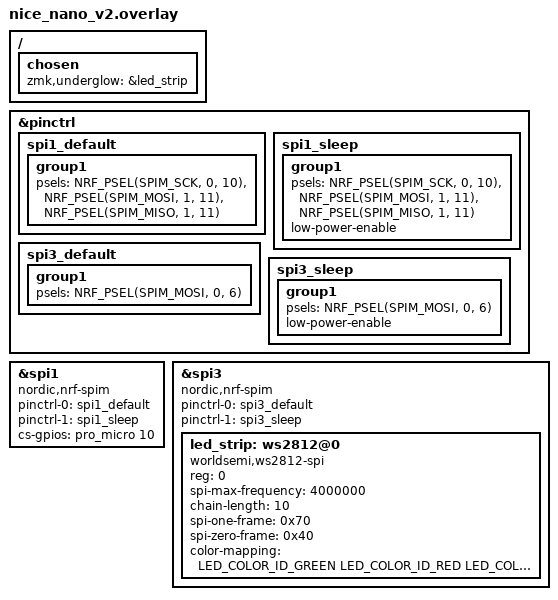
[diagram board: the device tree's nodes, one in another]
#include <dt-bindings/led/led.h>

&pinctrl {
    spi1_default: spi1_default {
        group1 {
            psels = <NRF_PSEL(SPIM_SCK,  0, 10)>,  /* D16 - CL/SCK  */
                    <NRF_PSEL(SPIM_MOSI, 1, 11)>,  /* D14 - DA/MOSI */
                    <NRF_PSEL(SPIM_MISO, 1, 11)>;  /* D14 - MISO (unused, same as MOSI) */
        };
    };
    spi1_sleep: spi1_sleep {
        group1 {
            psels = <NRF_PSEL(SPIM_SCK,  0, 10)>,
                    <NRF_PSEL(SPIM_MOSI, 1, 11)>,
                    <NRF_PSEL(SPIM_MISO, 1, 11)>;
            low-power-enable;
        };
    };
#ifndef MOUSE_PS2_ALT_PINS
    spi3_default: spi3_default {
        group1 {
            psels = <NRF_PSEL(SPIM_MOSI, 0, 6)>;
        };
    };
    spi3_sleep: spi3_sleep {
        group1 {
            psels = <NRF_PSEL(SPIM_MOSI, 0, 6)>;
            low-power-enable;
        };
    };
#endif
};

nice_view_spi: &spi1 {
    compatible = "nordic,nrf-spim";
    status = "okay";
    pinctrl-0 = <&spi1_default>;
    pinctrl-1 = <&spi1_sleep>;
    pinctrl-names = "default", "sleep";
    cs-gpios = <&pro_micro 10 GPIO_ACTIVE_HIGH>;  /* D10 - CS */
};

#ifndef MOUSE_PS2_ALT_PINS
&spi3 {
    compatible = "nordic,nrf-spim";
    status = "okay";
    pinctrl-0 = <&spi3_default>;
    pinctrl-1 = <&spi3_sleep>;
    pinctrl-names = "default", "sleep";
    led_strip: ws2812@0 {
        compatible = "worldsemi,ws2812-spi";
        reg = <0>;
        spi-max-frequency = <4000000>;
        chain-length = <10>;
        spi-one-frame = <0x70>;
        spi-zero-frame = <0x40>;
        color-mapping = <LED_COLOR_ID_GREEN LED_COLOR_ID_RED LED_COLOR_ID_BLUE>;
    };
};

/ {
    chosen {
        zmk,underglow = &led_strip;
    };
};
#endif  // MOUSE_PS2_ALT_PINS
